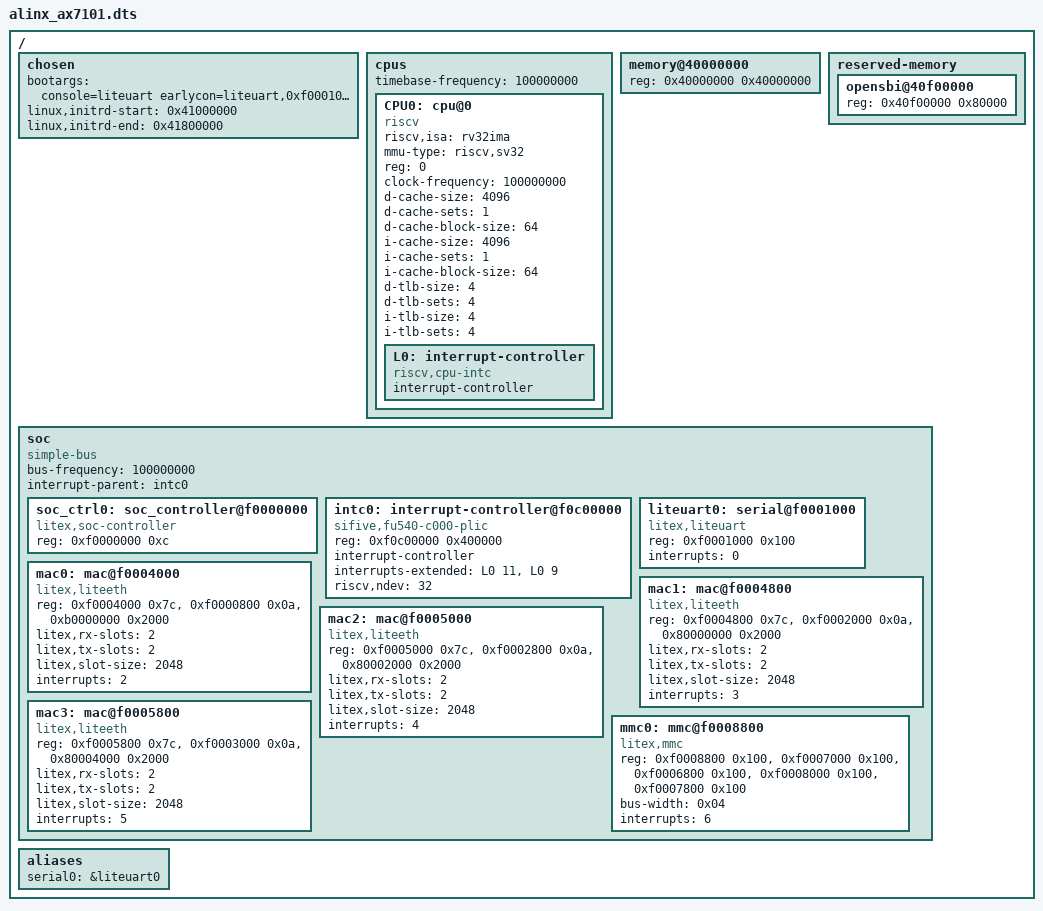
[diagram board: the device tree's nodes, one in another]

/dts-v1/;

/ {
        #address-cells = <1>;
        #size-cells    = <1>;


        chosen {
            bootargs = "console=liteuart earlycon=liteuart,0xf0001000 rootwait root=/dev/ram0";
            linux,initrd-start = <0x41000000>;
            linux,initrd-end   = <0x41800000>;
        };

        cpus {
            #address-cells = <1>;
            #size-cells    = <0>;
            timebase-frequency = <100000000>;

            CPU0: cpu@0 {
                device_type = "cpu";
                compatible = "riscv";
                riscv,isa = "rv32ima";
                mmu-type = "riscv,sv32";
                reg = <0>;
                clock-frequency = <100000000>;
                status = "okay";
                
                d-cache-size = <4096>;
                d-cache-sets = <1>;
                d-cache-block-size = <64>;

                i-cache-size = <4096>;
                i-cache-sets = <1>;
                i-cache-block-size = <64>;

                
                d-tlb-size = <4>;
                d-tlb-sets = <4>;

                i-tlb-size = <4>;
                i-tlb-sets = <4>;

                L0: interrupt-controller {
                    #interrupt-cells = <0x00000001>;
                    interrupt-controller;
                    compatible = "riscv,cpu-intc";
                };
            };

            
        };

        memory@40000000 {
            device_type = "memory";
            reg = <0x40000000 0x40000000>;
        };

        reserved-memory {
            #address-cells = <1>;
            #size-cells    = <1>;
            ranges;

            opensbi@40f00000 {
                reg = <0x40f00000 0x80000>;
            };

        };

        soc {
            #address-cells = <1>;
            #size-cells    = <1>;
            bus-frequency  = <100000000>;
            compatible = "simple-bus";
            interrupt-parent = <&intc0>;
            ranges;

            soc_ctrl0: soc_controller@f0000000 {
                compatible = "litex,soc-controller";
                reg = <0xf0000000 0xc>;
                status = "okay";
            };

            intc0: interrupt-controller@f0c00000 {
                compatible = "sifive,fu540-c000-plic", "sifive,plic-1.0.0";
                reg = <0xf0c00000 0x400000>;
                #address-cells = <0>;
                #interrupt-cells = <1>;
                interrupt-controller;
                interrupts-extended = <
                    &L0 11 &L0 9>;
                riscv,ndev = <32>;
            };

            liteuart0: serial@f0001000 {
                compatible = "litex,liteuart";
                reg = <0xf0001000 0x100>;
                interrupts = <0>;
                status = "okay";
            };

            mac0: mac@f0004000 {
                compatible = "litex,liteeth";
                reg = <0xf0004000 0x7c>,
                      <0xf0000800 0x0a>,
                      <0xb0000000 0x2000>;
                reg-names = "mac", "mdio", "buffer";
                litex,rx-slots = <2>;
                litex,tx-slots = <2>;
                litex,slot-size = <2048>;
                interrupts = <2>;
                status = "okay";
            };

            mac1: mac@f0004800 {
                compatible = "litex,liteeth";
                reg = <0xf0004800 0x7c>,
                      <0xf0002000 0x0a>,
                      <0x80000000 0x2000>;
                reg-names = "mac", "mdio", "buffer";
                litex,rx-slots = <2>;
                litex,tx-slots = <2>;
                litex,slot-size = <2048>;
                interrupts = <3>;
                status = "okay";
            };

            mac2: mac@f0005000 {
                compatible = "litex,liteeth";
                reg = <0xf0005000 0x7c>,
                      <0xf0002800 0x0a>,
                      <0x80002000 0x2000>;
                reg-names = "mac", "mdio", "buffer";
                litex,rx-slots = <2>;
                litex,tx-slots = <2>;
                litex,slot-size = <2048>;
                interrupts = <4>;
                status = "okay";
            };

            mac3: mac@f0005800 {
                compatible = "litex,liteeth";
                reg = <0xf0005800 0x7c>,
                      <0xf0003000 0x0a>,
                      <0x80004000 0x2000>;
                reg-names = "mac", "mdio", "buffer";
                litex,rx-slots = <2>;
                litex,tx-slots = <2>;
                litex,slot-size = <2048>;
                interrupts = <5>;
                status = "okay";
            };

            mmc0: mmc@f0008800 {
                compatible = "litex,mmc";
                reg = <0xf0008800 0x100>,
                      <0xf0007000 0x100>,
                      <0xf0006800 0x100>,
                      <0xf0008000 0x100>,
                      <0xf0007800 0x100>;
                bus-width = <0x04>;
                interrupts = <6>;
                status = "okay";
            };

        };

        aliases {

                serial0 = &liteuart0;

        };

};
